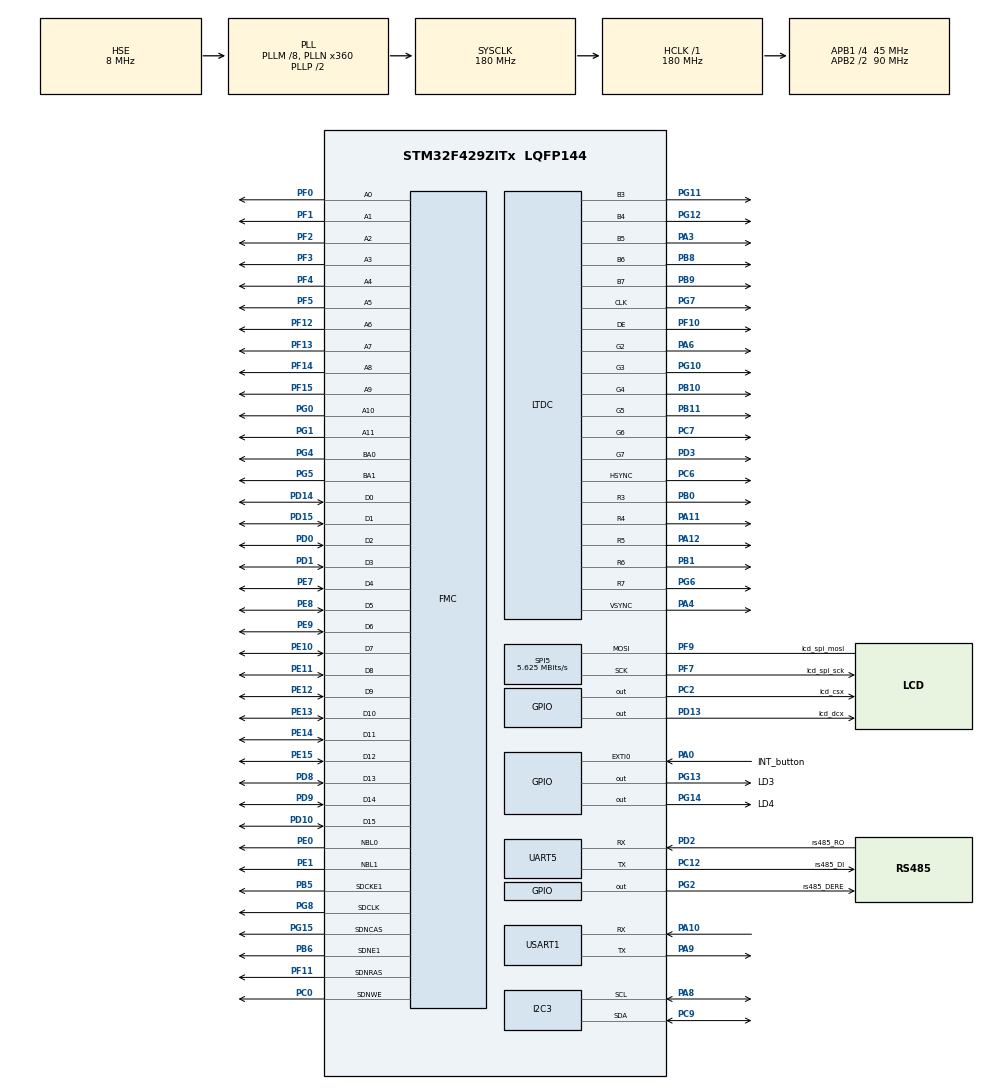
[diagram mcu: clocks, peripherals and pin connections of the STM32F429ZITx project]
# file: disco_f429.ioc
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ADC1.Channel-7\#ChannelRegularConversion=ADC_CHANNEL_VREFINT
ADC1.ContinuousConvMode=DISABLE
ADC1.EOCSelection=ADC_EOC_SEQ_CONV
ADC1.NbrOfConversion=1
ADC1.NbrOfConversionFlag=1
ADC1.Rank-7\#ChannelRegularConversion=1
ADC1.SamplingTime-7\#ChannelRegularConversion=ADC_SAMPLETIME_3CYCLES
ADC1.master=1
FMC.CASLatency1=FMC_SDRAM_CAS_LATENCY_3
FMC.ExitSelfRefreshDelay1=7
FMC.LoadToActiveDelay1=2
FMC.RCDDelay1=2
FMC.RPDelay1=2
FMC.RPDelay2=2
FMC.ReadPipeDelay1=FMC_SDRAM_RPIPE_DELAY_1
FMC.ReadPipeDelay2=FMC_SDRAM_RPIPE_DELAY_1
FMC.RowCycleDelay1=7
FMC.RowCycleDelay2=7
FMC.SDClockPeriod1=FMC_SDRAM_CLOCK_PERIOD_2
FMC.SDClockPeriod2=FMC_SDRAM_CLOCK_PERIOD_2
FMC.SelfRefreshTime1=4
FMC.WriteRecoveryTime1=2
FREERTOS.HEAP_NUMBER=1
FREERTOS.Queues01=adc_queue,1,float,0,Static,adc_queueBuffer,adc_queueControlBlock
FREERTOS.Tasks01=defaultTask,8,128,StartDefaultTask,Default,NULL,Static,defaultTaskBuffer,defaultTaskControlBlock;lcd_task,24,1024,lcd_task_func,As external,NULL,Static,lcd_taskBuffer,lcd_taskControlBlock;button_task,40,128,button_task_func,As external,NULL,Static,button_taskBuffer,button_taskControlBlock;led_task,40,128,led_task_func,As external,NULL,Static,led_taskBuffer,led_taskControlBlock;adc_task,24,256,adc_task_func,As external,NULL,Static,adc_taskBuffer,adc_taskControlBlock;modbus_task,24,128,modbus_task_func,As external,NULL,Static,modbus_taskBuffer,modbus_taskControlBlock
FREERTOS.configCHECK_FOR_STACK_OVERFLOW=2
FREERTOS.configTOTAL_HEAP_SIZE=16384
FREERTOS.configUSE_NEWLIB_REENTRANT=0
LTDC.ActiveH=320
LTDC.ActiveW=240
LTDC.Alpha_L0=255
LTDC.FBStartAdress_L0=0xD0000000
LTDC.HBP=20
LTDC.HFP=10
LTDC.HSync=10
LTDC.ImageHeight_L0=320
LTDC.ImageWidth_L0=240
LTDC.Layers=0
LTDC.PixelFormat_L0=LTDC_PIXEL_FORMAT_RGB565
LTDC.VBP=2
LTDC.VFP=4
LTDC.VSync=2
LTDC.WindowX1_L0=240
LTDC.WindowY1_L0=320
Mcu.Family=STM32F4
Mcu.Name=STM32F429ZITx
Mcu.Package=LQFP144
NVIC.EXTI0_IRQn=true\:5\:0\:false\:false\:true\:true\:true\:true\:true
NVIC.PriorityGroup=NVIC_PRIORITYGROUP_4
NVIC.TIM2_IRQn=true\:15\:0\:false\:false\:true\:false\:false\:true\:true
NVIC.TimeBase=TIM2_IRQn
NVIC.TimeBaseIP=TIM2
NVIC.USART1_IRQn=true\:5\:0\:false\:false\:false\:true\:true\:true\:true
PA0/WKUP.GPIO_Label=INT_button
PA0/WKUP.GPIO_ModeDefaultEXTI=GPIO_MODE_IT_RISING
PA0/WKUP.GPIO_PuPd=GPIO_NOPULL
PA0/WKUP.Signal=GPXTI0
PA10.Mode=Asynchronous
PA10.Signal=USART1_RX
PA11.Mode=RGB565
PA11.Signal=LTDC_R4
PA12.Mode=RGB565
PA12.Signal=LTDC_R5
PA13.Mode=Serial_Wire
PA13.Signal=SYS_JTMS-SWDIO
PA14.Mode=Serial_Wire
PA14.Signal=SYS_JTCK-SWCLK
PA3.Mode=RGB565
PA3.Signal=LTDC_B5
PA4.Mode=RGB565
PA4.Signal=LTDC_VSYNC
PA6.Mode=RGB565
PA6.Signal=LTDC_G2
PA8.Mode=I2C
PA8.Signal=I2C3_SCL
PA9.Mode=Asynchronous
PA9.Signal=USART1_TX
PB0.Mode=RGB565
PB0.Signal=LTDC_R3
PB1.Mode=RGB565
PB1.Signal=LTDC_R6
PB10.Mode=RGB565
PB10.Signal=LTDC_G4
PB11.Mode=RGB565
PB11.Signal=LTDC_G5
PB5.Mode=SdramChipSelect2_1
PB5.Signal=FMC_SDCKE1
PB6.Mode=SdramChipSelect2_1
PB6.Signal=FMC_SDNE1
PB8.Mode=RGB565
PB8.Signal=LTDC_B6
PB9.Mode=RGB565
PB9.Signal=LTDC_B7
PC0.Signal=FMC_SDNWE
PC12.GPIO_Label=rs485_DI
PC12.Mode=Asynchronous
PC12.Signal=UART5_TX
PC2.GPIO_Label=lcd_csx
PC2.GPIO_Speed=GPIO_SPEED_FREQ_HIGH
PC2.PinState=GPIO_PIN_SET
PC2.Signal=GPIO_Output
PC6.Mode=RGB565
PC6.Signal=LTDC_HSYNC
PC7.Mode=RGB565
PC7.Signal=LTDC_G6
PC9.Mode=I2C
PC9.Signal=I2C3_SDA
PD0.Signal=FMC_D2_DA2
PD1.Signal=FMC_D3_DA3
PD10.Signal=FMC_D15_DA15
PD13.GPIO_Label=lcd_dcx
PD13.Signal=GPIO_Output
PD14.Signal=FMC_D0_DA0
PD15.Signal=FMC_D1_DA1
PD2.GPIO_Label=rs485_RO
PD2.Mode=Asynchronous
PD2.Signal=UART5_RX
PD3.Mode=RGB565
PD3.Signal=LTDC_G7
PD8.Signal=FMC_D13_DA13
PD9.Signal=FMC_D14_DA14
PE0.Signal=FMC_NBL0
PE1.Signal=FMC_NBL1
PE10.Signal=FMC_D7_DA7
PE11.Signal=FMC_D8_DA8
PE12.Signal=FMC_D9_DA9
PE13.Signal=FMC_D10_DA10
PE14.Signal=FMC_D11_DA11
PE15.Signal=FMC_D12_DA12
PE7.Signal=FMC_D4_DA4
PE8.Signal=FMC_D5_DA5
PE9.Signal=FMC_D6_DA6
PF0.Signal=FMC_A0
PF1.Signal=FMC_A1
PF10.Mode=RGB565
PF10.Signal=LTDC_DE
PF11.Signal=FMC_SDNRAS
PF12.Signal=FMC_A6
PF13.Signal=FMC_A7
PF14.Signal=FMC_A8
PF15.Signal=FMC_A9
PF2.Signal=FMC_A2
PF3.Signal=FMC_A3
PF4.Signal=FMC_A4
PF5.Signal=FMC_A5
PF7.GPIO_Label=lcd_spi_sck
PF7.Mode=Simplex_Bidirectional_Master
PF7.Signal=SPI5_SCK
PF9.GPIO_Label=lcd_spi_mosi
PF9.Mode=Simplex_Bidirectional_Master
PF9.Signal=SPI5_MOSI
PG0.Signal=FMC_A10
PG1.Signal=FMC_A11
PG10.Mode=RGB565
PG10.Signal=LTDC_G3
PG11.Mode=RGB565
PG11.Signal=LTDC_B3
PG12.Mode=RGB565
PG12.Signal=LTDC_B4
PG13.GPIO_Label=LD3
PG13.PinState=GPIO_PIN_RESET
PG13.Signal=GPIO_Output
PG14.GPIO_Label=LD4
PG14.PinState=GPIO_PIN_RESET
PG14.Signal=GPIO_Output
PG15.Signal=FMC_SDNCAS
PG2.GPIO_Label=rs485_DERE
PG2.GPIO_Speed=GPIO_SPEED_FREQ_VERY_HIGH
PG2.Signal=GPIO_Output
PG4.Signal=FMC_A14_BA0
PG5.Signal=FMC_A15_BA1
PG6.Mode=RGB565
PG6.Signal=LTDC_R7
PG7.Mode=RGB565
PG7.Signal=LTDC_CLK
PG8.Signal=FMC_SDCLK
PH0/OSC_IN.Mode=HSE-External-Oscillator
PH0/OSC_IN.Signal=RCC_OSC_IN
PH1/OSC_OUT.Mode=HSE-External-Oscillator
PH1/OSC_OUT.Signal=RCC_OSC_OUT
ProjectManager.HeapSize=0x200
ProjectManager.StackSize=0x400
ProjectManager.TargetToolchain=STM32CubeIDE
RCC.48MHZClocksFreq_Value=51428571.428571425
RCC.AHBFreq_Value=180000000
RCC.APB1CLKDivider=RCC_HCLK_DIV4
RCC.APB1Freq_Value=45000000
RCC.APB1TimFreq_Value=90000000
RCC.APB2CLKDivider=RCC_HCLK_DIV2
RCC.APB2Freq_Value=90000000
RCC.APB2TimFreq_Value=180000000
RCC.CortexFreq_Value=180000000
RCC.HCLKFreq_Value=180000000
RCC.HSE_VALUE=8000000
RCC.HSI_VALUE=16000000
RCC.LSE_VALUE=32768
RCC.PLLM=8
RCC.PLLN=360
RCC.PLLQ=7
RCC.PLLSAIDivR=RCC_PLLSAIDIVR_8
RCC.PLLSAIN=192
RCC.PLLSAIR=4
RCC.PLLSourceVirtual=RCC_PLLSOURCE_HSE
RCC.SYSCLKFreq_VALUE=180000000
RCC.SYSCLKSource=RCC_SYSCLKSOURCE_PLLCLK
RCC.VCOOutputFreq_Value=360000000
SH.FMC_A0.0=FMC_A0,12b-sda1
SH.FMC_A1.0=FMC_A1,12b-sda1
SH.FMC_A10.0=FMC_A10,12b-sda1
SH.FMC_A11.0=FMC_A11,12b-sda1
SH.FMC_A14_BA0.0=FMC_BA0,FourSdramBanks1
SH.FMC_A15_BA1.0=FMC_BA1,FourSdramBanks1
SH.FMC_A2.0=FMC_A2,12b-sda1
SH.FMC_A3.0=FMC_A3,12b-sda1
SH.FMC_A4.0=FMC_A4,12b-sda1
SH.FMC_A5.0=FMC_A5,12b-sda1
SH.FMC_A6.0=FMC_A6,12b-sda1
SH.FMC_A7.0=FMC_A7,12b-sda1
SH.FMC_A8.0=FMC_A8,12b-sda1
SH.FMC_A9.0=FMC_A9,12b-sda1
SH.FMC_D0_DA0.0=FMC_D0,sd-16b-d1
SH.FMC_D10_DA10.0=FMC_D10,sd-16b-d1
SH.FMC_D11_DA11.0=FMC_D11,sd-16b-d1
SH.FMC_D12_DA12.0=FMC_D12,sd-16b-d1
SH.FMC_D13_DA13.0=FMC_D13,sd-16b-d1
SH.FMC_D14_DA14.0=FMC_D14,sd-16b-d1
SH.FMC_D15_DA15.0=FMC_D15,sd-16b-d1
SH.FMC_D1_DA1.0=FMC_D1,sd-16b-d1
SH.FMC_D2_DA2.0=FMC_D2,sd-16b-d1
SH.FMC_D3_DA3.0=FMC_D3,sd-16b-d1
SH.FMC_D4_DA4.0=FMC_D4,sd-16b-d1
SH.FMC_D5_DA5.0=FMC_D5,sd-16b-d1
SH.FMC_D6_DA6.0=FMC_D6,sd-16b-d1
SH.FMC_D7_DA7.0=FMC_D7,sd-16b-d1
SH.FMC_D8_DA8.0=FMC_D8,sd-16b-d1
SH.FMC_D9_DA9.0=FMC_D9,sd-16b-d1
SH.FMC_NBL0.0=FMC_NBL0,Sd2ByteEnable1
SH.FMC_NBL1.0=FMC_NBL1,Sd2ByteEnable1
SH.FMC_SDCLK.0=FMC_SDCLK,12b-sda1
SH.FMC_SDNCAS.0=FMC_SDNCAS,12b-sda1
SH.FMC_SDNRAS.0=FMC_SDNRAS,12b-sda1
SH.FMC_SDNWE.0=FMC_SDNWE,12b-sda1
SPI5.BaudRatePrescaler=SPI_BAUDRATEPRESCALER_16
SPI5.CalculateBaudRate=5.625 MBits/s
SPI5.Direction=SPI_DIRECTION_1LINE
SPI5.Mode=SPI_MODE_MASTER
SPI5.VirtualType=VM_MASTER
STMicroelectronics.X-CUBE-TOUCHGFX.4.23.2.ApplicationCcGraphicsJjApplication=TouchGFXOoGenerator
STMicroelectronics.X-CUBE-TOUCHGFX.4.23.2.tgfx_address1=0xD0000000
STMicroelectronics.X-CUBE-TOUCHGFX.4.23.2.tgfx_custom_height=240
STMicroelectronics.X-CUBE-TOUCHGFX.4.23.2.tgfx_custom_width=320
STMicroelectronics.X-CUBE-TOUCHGFX.4.23.2.tgfx_location=By Address
STMicroelectronics.X-CUBE-TOUCHGFX.4.23.2_IsPackSelfContextualization=true
TIM7.Prescaler=83
TIM7.TIM_MasterOutputTrigger=TIM_TRGO_UPDATE
UART5.VirtualMode=Asynchronous
USART1.VirtualMode=VM_ASYNC
VP_ADC1_Vref_Input.Mode=IN-Vrefint
VP_CRC_VS_CRC.Mode=CRC_Activate
VP_DMA2D_VS_DMA2D.Mode=DMA2D_Activate
VP_FREERTOS_VS_CMSIS_V2.Mode=CMSIS_V2
VP_STMicroelectronics.X-CUBE-TOUCHGFX_VS_GraphicsJjApplication_4.23.2.Mode=GraphicsJjApplication
VP_SYS_VS_tim2.Mode=TIM2
VP_TIM7_VS_ClockSourceINT.Mode=Enable_Timer
board=custom

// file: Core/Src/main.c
/* USER CODE BEGIN Header */
/**
  ******************************************************************************
  * @file           : main.c
  * @brief          : Main program body
  ******************************************************************************
  * @attention
  *
  * Copyright (c) 2024 STMicroelectronics.
  * All rights reserved.
  *
  * This software is licensed under terms that can be found in the LICENSE file
  * in the root directory of this software component.
  * If no LICENSE file comes with this software, it is provided AS-IS.
  *
  ******************************************************************************
  */
/* USER CODE END Header */
#include "main.h"
#include "cmsis_os.h"
#include "app_touchgfx.h"

/* USER CODE BEGIN Includes */
#include <stdio.h>
#include <stdlib.h>
#include <string.h>
#include "user.h"
#include "sdram.h"
#include "lcd.h"
#include "ili9341.h"
#include "stm32f429i_discovery.h"
#include "stm32f429i_discovery_lcd.h"
#ifdef __cplusplus
extern "C" int __io_putchar(int ch);
#else
int __io_putchar(int ch);
#endif

extern void MPU6050_Initialize(void);
extern void MPU6050_Process(void);
extern void dmpDataReady(void);
#define UART_RX_BUFFER_SZ 1
uint8_t uart_Data[UART_RX_BUFFER_SZ];

/* USER CODE END Includes */

typedef StaticTask_t osStaticThreadDef_t;
typedef StaticQueue_t osStaticMessageQDef_t;

ADC_HandleTypeDef hadc1;

CRC_HandleTypeDef hcrc;

I2C_HandleTypeDef hi2c3;

LTDC_HandleTypeDef hltdc;

SPI_HandleTypeDef hspi5;

TIM_HandleTypeDef htim7;

UART_HandleTypeDef huart5;
UART_HandleTypeDef huart1;

SDRAM_HandleTypeDef hsdram1;

/* Definitions for defaultTask */
osThreadId_t defaultTaskHandle;
uint32_t defaultTaskBuffer[ 128 ];
osStaticThreadDef_t defaultTaskControlBlock;
const osThreadAttr_t defaultTask_attributes = {
  .name = "defaultTask",
  .cb_mem = &defaultTaskControlBlock,
  .cb_size = sizeof(defaultTaskControlBlock),
  .stack_mem = &defaultTaskBuffer[0],
  .stack_size = sizeof(defaultTaskBuffer),
  .priority = (osPriority_t) osPriorityLow,
};
/* Definitions for lcd_task */
osThreadId_t lcd_taskHandle;
uint32_t lcd_taskBuffer[ 1024 ];
osStaticThreadDef_t lcd_taskControlBlock;
const osThreadAttr_t lcd_task_attributes = {
  .name = "lcd_task",
  .cb_mem = &lcd_taskControlBlock,
  .cb_size = sizeof(lcd_taskControlBlock),
  .stack_mem = &lcd_taskBuffer[0],
  .stack_size = sizeof(lcd_taskBuffer),
  .priority = (osPriority_t) osPriorityNormal,
};
/* Definitions for button_task */
osThreadId_t button_taskHandle;
uint32_t button_taskBuffer[ 128 ];
osStaticThreadDef_t button_taskControlBlock;
const osThreadAttr_t button_task_attributes = {
  .name = "button_task",
  .cb_mem = &button_taskControlBlock,
  .cb_size = sizeof(button_taskControlBlock),
  .stack_mem = &button_taskBuffer[0],
  .stack_size = sizeof(button_taskBuffer),
  .priority = (osPriority_t) osPriorityHigh,
};
/* Definitions for led_task */
osThreadId_t led_taskHandle;
uint32_t led_taskBuffer[ 128 ];
osStaticThreadDef_t led_taskControlBlock;
const osThreadAttr_t led_task_attributes = {
  .name = "led_task",
  .cb_mem = &led_taskControlBlock,
  .cb_size = sizeof(led_taskControlBlock),
  .stack_mem = &led_taskBuffer[0],
  .stack_size = sizeof(led_taskBuffer),
  .priority = (osPriority_t) osPriorityHigh,
};
/* Definitions for adc_task */
osThreadId_t adc_taskHandle;
uint32_t adc_taskBuffer[ 256 ];
osStaticThreadDef_t adc_taskControlBlock;
const osThreadAttr_t adc_task_attributes = {
  .name = "adc_task",
  .cb_mem = &adc_taskControlBlock,
  .cb_size = sizeof(adc_taskControlBlock),
  .stack_mem = &adc_taskBuffer[0],
  .stack_size = sizeof(adc_taskBuffer),
  .priority = (osPriority_t) osPriorityNormal,
};
/* Definitions for modbus_task */
osThreadId_t modbus_taskHandle;
uint32_t modbus_taskBuffer[ 128 ];
osStaticThreadDef_t modbus_taskControlBlock;
const osThreadAttr_t modbus_task_attributes = {
  .name = "modbus_task",
  .cb_mem = &modbus_taskControlBlock,
  .cb_size = sizeof(modbus_taskControlBlock),
  .stack_mem = &modbus_taskBuffer[0],
  .stack_size = sizeof(modbus_taskBuffer),
  .priority = (osPriority_t) osPriorityNormal,
};
/* Definitions for adc_queue */
osMessageQueueId_t adc_queueHandle;
uint8_t adc_queueBuffer[ 1 * sizeof( float ) ];
osStaticMessageQDef_t adc_queueControlBlock;
const osMessageQueueAttr_t adc_queue_attributes = {
  .name = "adc_queue",
  .cb_mem = &adc_queueControlBlock,
  .cb_size = sizeof(adc_queueControlBlock),
  .mq_mem = &adc_queueBuffer,
  .mq_size = sizeof(adc_queueBuffer)
};

void SystemClock_Config(void);
static void MX_GPIO_Init(void);
static void MX_USART1_UART_Init(void);
static void MX_SPI5_Init(void);
static void MX_ADC1_Init(void);
static void MX_TIM7_Init(void);
static void MX_UART5_Init(void);
static void MX_FMC_Init(void);
static void MX_LTDC_Init(void);
static void MX_I2C3_Init(void);
static void MX_CRC_Init(void);
void StartDefaultTask(void *argument);
extern void lcd_task_func(void *argument);
extern void button_task_func(void *argument);
extern void led_task_func(void *argument);
extern void adc_task_func(void *argument);
extern void modbus_task_func(void *argument);

int main(void)
{

  /* MCU Configuration--------------------------------------------------------*/

  /* Reset of all peripherals, Initializes the Flash interface and the Systick. */
  HAL_Init();

  /* USER CODE BEGIN Init */
  DWT_Init();
  /* USER CODE END Init */

  /* Configure the system clock */
  SystemClock_Config();

  /* Initialize all configured peripherals */
  MX_GPIO_Init();
  MX_USART1_UART_Init();
  MX_SPI5_Init();
  MX_ADC1_Init();
  MX_TIM7_Init();
  MX_UART5_Init();
  MX_FMC_Init();
  MX_LTDC_Init();
  MX_I2C3_Init();
  MX_CRC_Init();
  MX_TouchGFX_Init();
  /* Call PreOsInit function */
  MX_TouchGFX_PreOSInit();

  /* Init scheduler */
  osKernelInitialize();

  /* Create the queue(s) */
  /* creation of adc_queue */
  adc_queueHandle = osMessageQueueNew (1, sizeof(float), &adc_queue_attributes);

  /* Create the thread(s) */
  /* creation of defaultTask */
  defaultTaskHandle = osThreadNew(StartDefaultTask, NULL, &defaultTask_attributes);

  /* creation of lcd_task */
  lcd_taskHandle = osThreadNew(lcd_task_func, NULL, &lcd_task_attributes);

  /* creation of button_task */
  button_taskHandle = osThreadNew(button_task_func, NULL, &button_task_attributes);

  /* creation of led_task */
  led_taskHandle = osThreadNew(led_task_func, NULL, &led_task_attributes);

  /* creation of adc_task */
  adc_taskHandle = osThreadNew(adc_task_func, NULL, &adc_task_attributes);

  /* creation of modbus_task */
  modbus_taskHandle = osThreadNew(modbus_task_func, NULL, &modbus_task_attributes);

  /* Start scheduler */
  osKernelStart();

  /* We should never get here as control is now taken by the scheduler */

  /* Infinite loop */
  while (1)
  {

  }
}

void SystemClock_Config(void)
{
  RCC_OscInitTypeDef RCC_OscInitStruct = {0};
  RCC_ClkInitTypeDef RCC_ClkInitStruct = {0};

  /** Configure the main internal regulator output voltage
  */
  __HAL_RCC_PWR_CLK_ENABLE();
  __HAL_PWR_VOLTAGESCALING_CONFIG(PWR_REGULATOR_VOLTAGE_SCALE1);

  /** Initializes the RCC Oscillators according to the specified parameters
  * in the RCC_OscInitTypeDef structure.
  */
  RCC_OscInitStruct.OscillatorType = RCC_OSCILLATORTYPE_HSE;
  RCC_OscInitStruct.HSEState = RCC_HSE_ON;
  RCC_OscInitStruct.PLL.PLLState = RCC_PLL_ON;
  RCC_OscInitStruct.PLL.PLLSource = RCC_PLLSOURCE_HSE;
  RCC_OscInitStruct.PLL.PLLM = 8;
  RCC_OscInitStruct.PLL.PLLN = 360;
  RCC_OscInitStruct.PLL.PLLP = RCC_PLLP_DIV2;
  RCC_OscInitStruct.PLL.PLLQ = 7;
  if (HAL_RCC_OscConfig(&RCC_OscInitStruct) != HAL_OK)
  {
    Error_Handler();
  }

  /** Activate the Over-Drive mode
  */
  if (HAL_PWREx_EnableOverDrive() != HAL_OK)
  {
    Error_Handler();
  }

  /** Initializes the CPU, AHB and APB buses clocks
  */
  RCC_ClkInitStruct.ClockType = RCC_CLOCKTYPE_HCLK|RCC_CLOCKTYPE_SYSCLK
                              |RCC_CLOCKTYPE_PCLK1|RCC_CLOCKTYPE_PCLK2;
  RCC_ClkInitStruct.SYSCLKSource = RCC_SYSCLKSOURCE_PLLCLK;
  RCC_ClkInitStruct.AHBCLKDivider = RCC_SYSCLK_DIV1;
  RCC_ClkInitStruct.APB1CLKDivider = RCC_HCLK_DIV4;
  RCC_ClkInitStruct.APB2CLKDivider = RCC_HCLK_DIV2;

  if (HAL_RCC_ClockConfig(&RCC_ClkInitStruct, FLASH_LATENCY_5) != HAL_OK)
  {
    Error_Handler();
  }
}

static void MX_ADC1_Init(void)
{

  ADC_ChannelConfTypeDef sConfig = {0};

  /** Configure the global features of the ADC (Clock, Resolution, Data Alignment and number of conversion)
  */
  hadc1.Instance = ADC1;
  hadc1.Init.ClockPrescaler = ADC_CLOCK_SYNC_PCLK_DIV4;
  hadc1.Init.Resolution = ADC_RESOLUTION_12B;
  hadc1.Init.ScanConvMode = DISABLE;
  hadc1.Init.ContinuousConvMode = DISABLE;
  hadc1.Init.DiscontinuousConvMode = DISABLE;
  hadc1.Init.ExternalTrigConvEdge = ADC_EXTERNALTRIGCONVEDGE_NONE;
  hadc1.Init.ExternalTrigConv = ADC_SOFTWARE_START;
  hadc1.Init.DataAlign = ADC_DATAALIGN_RIGHT;
  hadc1.Init.NbrOfConversion = 1;
  hadc1.Init.DMAContinuousRequests = DISABLE;
  hadc1.Init.EOCSelection = ADC_EOC_SEQ_CONV;
  if (HAL_ADC_Init(&hadc1) != HAL_OK)
  {
    Error_Handler();
  }

  /** Configure for the selected ADC regular channel its corresponding rank in the sequencer and its sample time.
  */
  sConfig.Channel = ADC_CHANNEL_VREFINT;
  sConfig.Rank = 1;
  sConfig.SamplingTime = ADC_SAMPLETIME_3CYCLES;
  if (HAL_ADC_ConfigChannel(&hadc1, &sConfig) != HAL_OK)
  {
    Error_Handler();
  }

}

static void MX_CRC_Init(void)
{

  hcrc.Instance = CRC;
  if (HAL_CRC_Init(&hcrc) != HAL_OK)
  {
    Error_Handler();
  }

}

static void MX_I2C3_Init(void)
{

  hi2c3.Instance = I2C3;
  hi2c3.Init.ClockSpeed = 100000;
  hi2c3.Init.DutyCycle = I2C_DUTYCYCLE_2;
  hi2c3.Init.OwnAddress1 = 0;
  hi2c3.Init.AddressingMode = I2C_ADDRESSINGMODE_7BIT;
  hi2c3.Init.DualAddressMode = I2C_DUALADDRESS_DISABLE;
  hi2c3.Init.OwnAddress2 = 0;
  hi2c3.Init.GeneralCallMode = I2C_GENERALCALL_DISABLE;
  hi2c3.Init.NoStretchMode = I2C_NOSTRETCH_DISABLE;
  if (HAL_I2C_Init(&hi2c3) != HAL_OK)
  {
    Error_Handler();
  }

  /** Configure Analogue filter
  */
  if (HAL_I2CEx_ConfigAnalogFilter(&hi2c3, I2C_ANALOGFILTER_ENABLE) != HAL_OK)
  {
    Error_Handler();
  }

  /** Configure Digital filter
  */
  if (HAL_I2CEx_ConfigDigitalFilter(&hi2c3, 0) != HAL_OK)
  {
    Error_Handler();
  }

}

static void MX_LTDC_Init(void)
{

  LTDC_LayerCfgTypeDef pLayerCfg = {0};

  hltdc.Instance = LTDC;
  hltdc.Init.HSPolarity = LTDC_HSPOLARITY_AL;
  hltdc.Init.VSPolarity = LTDC_VSPOLARITY_AL;
  hltdc.Init.DEPolarity = LTDC_DEPOLARITY_AL;
  hltdc.Init.PCPolarity = LTDC_PCPOLARITY_IPC;
  hltdc.Init.HorizontalSync = 9;
  hltdc.Init.VerticalSync = 1;
  hltdc.Init.AccumulatedHBP = 29;
  hltdc.Init.AccumulatedVBP = 3;
  hltdc.Init.AccumulatedActiveW = 269;
  hltdc.Init.AccumulatedActiveH = 323;
  hltdc.Init.TotalWidth = 279;
  hltdc.Init.TotalHeigh = 327;
  hltdc.Init.Backcolor.Blue = 0;
  hltdc.Init.Backcolor.Green = 0;
  hltdc.Init.Backcolor.Red = 0;
  if (HAL_LTDC_Init(&hltdc) != HAL_OK)
  {
    Error_Handler();
  }
  pLayerCfg.WindowX0 = 0;
  pLayerCfg.WindowX1 = 240;
  pLayerCfg.WindowY0 = 0;
  pLayerCfg.WindowY1 = 320;
  pLayerCfg.PixelFormat = LTDC_PIXEL_FORMAT_RGB565;
  pLayerCfg.Alpha = 255;
  pLayerCfg.Alpha0 = 0;
  pLayerCfg.BlendingFactor1 = LTDC_BLENDING_FACTOR1_CA;
  pLayerCfg.BlendingFactor2 = LTDC_BLENDING_FACTOR2_CA;
  pLayerCfg.FBStartAdress = 0xD0000000;
  pLayerCfg.ImageWidth = 240;
  pLayerCfg.ImageHeight = 320;
  pLayerCfg.Backcolor.Blue = 0;
  pLayerCfg.Backcolor.Green = 0;
  pLayerCfg.Backcolor.Red = 0;
  if (HAL_LTDC_ConfigLayer(&hltdc, &pLayerCfg, 0) != HAL_OK)
  {
    Error_Handler();
  }

}

static void MX_SPI5_Init(void)
{

  /* USER CODE BEGIN SPI5_Init 1 */
       /* SPI baudrate is set to 5.25 MHz (PCLK2/SPI_BaudRatePrescaler = 84/16 = 5.25 MHz)
       to verify these constraints:
       - ILI9341 LCD SPI interface max baudrate is 10MHz for write and 6.66MHz for read
       - l3gd20 SPI interface max baudrate is 10MHz for write/read
       - PCLK2 frequency is set to 84 MHz
    */

    /* On STM32F429I-Discovery, LCD ID cannot be read then keep a common configuration */
    /* for LCD and GYRO (SPI_DIRECTION_2LINES) */
    /* Note: To read a register a LCD, SPI_DIRECTION_1LINE should be set */
  /* USER CODE END SPI5_Init 1 */
  /* SPI5 parameter configuration*/
  hspi5.Instance = SPI5;
  hspi5.Init.Mode = SPI_MODE_MASTER;
  hspi5.Init.Direction = SPI_DIRECTION_1LINE;
  hspi5.Init.DataSize = SPI_DATASIZE_8BIT;
  hspi5.Init.CLKPolarity = SPI_POLARITY_LOW;
  hspi5.Init.CLKPhase = SPI_PHASE_1EDGE;
  hspi5.Init.NSS = SPI_NSS_SOFT;
  hspi5.Init.BaudRatePrescaler = SPI_BAUDRATEPRESCALER_16;
  hspi5.Init.FirstBit = SPI_FIRSTBIT_MSB;
  hspi5.Init.TIMode = SPI_TIMODE_DISABLE;
  hspi5.Init.CRCCalculation = SPI_CRCCALCULATION_DISABLE;
  hspi5.Init.CRCPolynomial = 10;
  if (HAL_SPI_Init(&hspi5) != HAL_OK)
  {
    Error_Handler();
  }
  /* USER CODE BEGIN SPI5_Init 2 */
  //SPI_HALtoBSP_bind(&hspi5);
  *Get_BSP_SPIHandle() = hspi5;
  /* USER CODE END SPI5_Init 2 */

}

static void MX_TIM7_Init(void)
{

  TIM_MasterConfigTypeDef sMasterConfig = {0};

  htim7.Instance = TIM7;
  htim7.Init.Prescaler = 83;
  htim7.Init.CounterMode = TIM_COUNTERMODE_UP;
  htim7.Init.Period = 65535;
  htim7.Init.AutoReloadPreload = TIM_AUTORELOAD_PRELOAD_DISABLE;
  if (HAL_TIM_Base_Init(&htim7) != HAL_OK)
  {
    Error_Handler();
  }
  sMasterConfig.MasterOutputTrigger = TIM_TRGO_UPDATE;
  sMasterConfig.MasterSlaveMode = TIM_MASTERSLAVEMODE_DISABLE;
  if (HAL_TIMEx_MasterConfigSynchronization(&htim7, &sMasterConfig) != HAL_OK)
  {
    Error_Handler();
  }
  /* USER CODE BEGIN TIM7_Init 2 */
   HAL_TIM_Base_Start(&htim7);
   __HAL_TIM_CLEAR_FLAG(&htim7, TIM_FLAG_UPDATE);
  /* USER CODE END TIM7_Init 2 */

}

static void MX_UART5_Init(void)
{

  huart5.Instance = UART5;
  huart5.Init.BaudRate = 115200;
  huart5.Init.WordLength = UART_WORDLENGTH_8B;
  huart5.Init.StopBits = UART_STOPBITS_1;
  huart5.Init.Parity = UART_PARITY_NONE;
  huart5.Init.Mode = UART_MODE_TX_RX;
  huart5.Init.HwFlowCtl = UART_HWCONTROL_NONE;
  huart5.Init.OverSampling = UART_OVERSAMPLING_16;
  if (HAL_UART_Init(&huart5) != HAL_OK)
  {
    Error_Handler();
  }

}

static void MX_USART1_UART_Init(void)
{

  huart1.Instance = USART1;
  huart1.Init.BaudRate = 115200;
  huart1.Init.WordLength = UART_WORDLENGTH_8B;
  huart1.Init.StopBits = UART_STOPBITS_1;
  huart1.Init.Parity = UART_PARITY_NONE;
  huart1.Init.Mode = UART_MODE_TX_RX;
  huart1.Init.HwFlowCtl = UART_HWCONTROL_NONE;
  huart1.Init.OverSampling = UART_OVERSAMPLING_16;
  if (HAL_UART_Init(&huart1) != HAL_OK)
  {
    Error_Handler();
  }
  /* USER CODE BEGIN USART1_Init 2 */
  HAL_UART_Receive_IT(&huart1, uart_Data, UART_RX_BUFFER_SZ);
  /* USER CODE END USART1_Init 2 */

}

/* FMC initialization function */
static void MX_FMC_Init(void)
{

  FMC_SDRAM_TimingTypeDef SdramTiming = {0};

  /* USER CODE BEGIN FMC_Init 1 */
    /* Timing configuration for 90 Mhz of SD clock frequency (180Mhz/2) */
  /* USER CODE END FMC_Init 1 */

  /** Perform the SDRAM1 memory initialization sequence
  */
  hsdram1.Instance = FMC_SDRAM_DEVICE;
  /* hsdram1.Init */
  hsdram1.Init.SDBank = FMC_SDRAM_BANK2;
  hsdram1.Init.ColumnBitsNumber = FMC_SDRAM_COLUMN_BITS_NUM_8;
  hsdram1.Init.RowBitsNumber = FMC_SDRAM_ROW_BITS_NUM_12;
  hsdram1.Init.MemoryDataWidth = FMC_SDRAM_MEM_BUS_WIDTH_16;
  hsdram1.Init.InternalBankNumber = FMC_SDRAM_INTERN_BANKS_NUM_4;
  hsdram1.Init.CASLatency = FMC_SDRAM_CAS_LATENCY_3;
  hsdram1.Init.WriteProtection = FMC_SDRAM_WRITE_PROTECTION_DISABLE;
  hsdram1.Init.SDClockPeriod = FMC_SDRAM_CLOCK_PERIOD_2;
  hsdram1.Init.ReadBurst = FMC_SDRAM_RBURST_DISABLE;
  hsdram1.Init.ReadPipeDelay = FMC_SDRAM_RPIPE_DELAY_1;
  /* SdramTiming */
  SdramTiming.LoadToActiveDelay = 2;
  SdramTiming.ExitSelfRefreshDelay = 7;
  SdramTiming.SelfRefreshTime = 4;
  SdramTiming.RowCycleDelay = 7;
  SdramTiming.WriteRecoveryTime = 2;
  SdramTiming.RPDelay = 2;
  SdramTiming.RCDDelay = 2;

  if (HAL_SDRAM_Init(&hsdram1, &SdramTiming) != HAL_OK)
  {
    Error_Handler( );
  }

  /* USER CODE BEGIN FMC_Init 2 */
  user_SDRAM_Initialization_sequence(REFRESH_COUNT);
  /* USER CODE END FMC_Init 2 */
}

static void MX_GPIO_Init(void)
{
  GPIO_InitTypeDef GPIO_InitStruct = {0};

  /* GPIO Ports Clock Enable */
  __HAL_RCC_GPIOF_CLK_ENABLE();
  __HAL_RCC_GPIOH_CLK_ENABLE();
  __HAL_RCC_GPIOC_CLK_ENABLE();
  __HAL_RCC_GPIOA_CLK_ENABLE();
  __HAL_RCC_GPIOB_CLK_ENABLE();
  __HAL_RCC_GPIOG_CLK_ENABLE();
  __HAL_RCC_GPIOE_CLK_ENABLE();
  __HAL_RCC_GPIOD_CLK_ENABLE();

  /*Configure GPIO pin Output Level */
  HAL_GPIO_WritePin(lcd_csx_GPIO_Port, lcd_csx_Pin, GPIO_PIN_SET);

  /*Configure GPIO pin Output Level */
  HAL_GPIO_WritePin(lcd_dcx_GPIO_Port, lcd_dcx_Pin, GPIO_PIN_RESET);

  /*Configure GPIO pin Output Level */
  HAL_GPIO_WritePin(GPIOG, rs485_DERE_Pin|LD3_Pin|LD4_Pin, GPIO_PIN_RESET);

  /*Configure GPIO pin : lcd_csx_Pin */
  GPIO_InitStruct.Pin = lcd_csx_Pin;
  GPIO_InitStruct.Mode = GPIO_MODE_OUTPUT_PP;
  GPIO_InitStruct.Pull = GPIO_NOPULL;
  GPIO_InitStruct.Speed = GPIO_SPEED_FREQ_HIGH;
  HAL_GPIO_Init(lcd_csx_GPIO_Port, &GPIO_InitStruct);

  /*Configure GPIO pin : INT_button_Pin */
  GPIO_InitStruct.Pin = INT_button_Pin;
  GPIO_InitStruct.Mode = GPIO_MODE_IT_RISING;
  GPIO_InitStruct.Pull = GPIO_NOPULL;
  HAL_GPIO_Init(INT_button_GPIO_Port, &GPIO_InitStruct);

  /*Configure GPIO pin : lcd_dcx_Pin */
  GPIO_InitStruct.Pin = lcd_dcx_Pin;
  GPIO_InitStruct.Mode = GPIO_MODE_OUTPUT_PP;
  GPIO_InitStruct.Pull = GPIO_NOPULL;
  GPIO_InitStruct.Speed = GPIO_SPEED_FREQ_LOW;
  HAL_GPIO_Init(lcd_dcx_GPIO_Port, &GPIO_InitStruct);

  /*Configure GPIO pin : rs485_DERE_Pin */
  GPIO_InitStruct.Pin = rs485_DERE_Pin;
  GPIO_InitStruct.Mode = GPIO_MODE_OUTPUT_PP;
  GPIO_InitStruct.Pull = GPIO_NOPULL;
  GPIO_InitStruct.Speed = GPIO_SPEED_FREQ_VERY_HIGH;
  HAL_GPIO_Init(rs485_DERE_GPIO_Port, &GPIO_InitStruct);

  /*Configure GPIO pins : LD3_Pin LD4_Pin */
  GPIO_InitStruct.Pin = LD3_Pin|LD4_Pin;
  GPIO_InitStruct.Mode = GPIO_MODE_OUTPUT_PP;
  GPIO_InitStruct.Pull = GPIO_NOPULL;
  GPIO_InitStruct.Speed = GPIO_SPEED_FREQ_LOW;
  HAL_GPIO_Init(GPIOG, &GPIO_InitStruct);

  /* EXTI interrupt init*/
  HAL_NVIC_SetPriority(EXTI0_IRQn, 5, 0);
  HAL_NVIC_EnableIRQ(EXTI0_IRQn);

}

/* USER CODE BEGIN 4 */
void HAL_UART_RxCpltCallback(UART_HandleTypeDef *huart)
{
  HAL_GPIO_TogglePin(GPIOG,LD3_Pin|LD4_Pin);
  HAL_UART_Receive_IT(huart, uart_Data, UART_RX_BUFFER_SZ);
}

int __io_putchar(int ch)
{
  HAL_UART_Transmit(&huart1, (uint8_t *)&ch, 1, 10);
  return ch;
}

/* USER CODE END 4 */

void StartDefaultTask(void *argument)
{
  for(;;)
  {
    osDelay(1);
  }
}

void HAL_TIM_PeriodElapsedCallback(TIM_HandleTypeDef *htim)
{
  if (htim->Instance == TIM2)
  {
    HAL_IncTick();
  }
}

void Error_Handler(void)
{
  __disable_irq();
  while (1)
  {
  }
}

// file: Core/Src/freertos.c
/* USER CODE BEGIN Header */
/**
  ******************************************************************************
  * File Name          : freertos.c
  * Description        : Code for freertos applications
  ******************************************************************************
  * @attention
  *
  * Copyright (c) 2025 STMicroelectronics.
  * All rights reserved.
  *
  * This software is licensed under terms that can be found in the LICENSE file
  * in the root directory of this software component.
  * If no LICENSE file comes with this software, it is provided AS-IS.
  *
  ******************************************************************************
  */
/* USER CODE END Header */

#include "FreeRTOS.h"
#include "task.h"
#include "main.h"

/* USER CODE BEGIN Includes */
#include "user.h"
/* USER CODE END Includes */

/* Hook prototypes */
void vApplicationStackOverflowHook(xTaskHandle xTask, signed char *pcTaskName);

/* USER CODE BEGIN 4 */
void vApplicationStackOverflowHook(xTaskHandle xTask, signed char *pcTaskName)
{
  HARDFAULT;
   /* Run time stack overflow checking is performed if
   configCHECK_FOR_STACK_OVERFLOW is defined to 1 or 2. This hook function is
   called if a stack overflow is detected. */
}
/* USER CODE END 4 */
